# ACCESS_VALUES register map
Registers are 32-bit, access not given, no defined reset value unless marked. A register's access mark holds for its fields unless they carry their own. Offsets are from the block's base; lines under a group give offsets from that group; [hi:lo] are bit positions; {n}, {i} and the like mark numbered series; 'fields as' and 'values as' point back to an identical list; <NAME> marks a mode.

## Memory map
0x40000000 DEV

## DEV
Base 0x40000000
0x00 WRITE_ACCESS write — States `write`: read as absent, so the mode is the one its fields imply.
  [0] A ro
0x04 READ_CLEAR_ACCESS read/clear — States `read/clear`, with no field: read write.
0x08 INHERITING — States no access: read write, as every register of the file without a mode of its fields.
0x0C BAD_ACTION on read: clearonread — A readAction and a modifiedWriteValues no SVD defines.
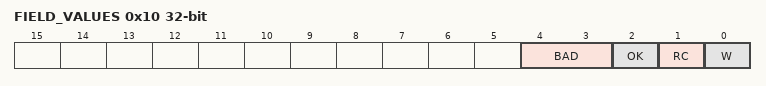
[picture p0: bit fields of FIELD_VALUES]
0x10 FIELD_VALUES — Fields stating `write` and `read/clear`: read as absent, so the field takes its register's mode.
  [4:3] BAD on read: clearonread — Effects no SVD defines, and a set with a usage no SVD defines.
    0=A
  [2] OK ro
  [1] RC read/clear — States `read/clear`.
  [0] W write — States `write`.
